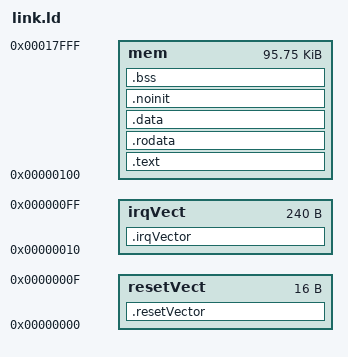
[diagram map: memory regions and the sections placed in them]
/*
 * Copyright (c) 2018 TU Dresden
 * All rights reserved.
 *
 * Redistribution and use in source and binary forms, with or without
 * modification, are permitted provided that the following conditions are
 * met: redistributions of source code must retain the above copyright
 * notice, this list of conditions and the following disclaimer;
 * redistributions in binary form must reproduce the above copyright
 * notice, this list of conditions and the following disclaimer in the
 * documentation and/or other materials provided with the distribution;
 * neither the name of the copyright holders nor the names of its
 * contributors may be used to endorse or promote products derived from
 * this software without specific prior written permission.
 *
 * THIS SOFTWARE IS PROVIDED BY THE COPYRIGHT HOLDERS AND CONTRIBUTORS
 * "AS IS" AND ANY EXPRESS OR IMPLIED WARRANTIES, INCLUDING, BUT NOT
 * LIMITED TO, THE IMPLIED WARRANTIES OF MERCHANTABILITY AND FITNESS FOR
 * A PARTICULAR PURPOSE ARE DISCLAIMED. IN NO EVENT SHALL THE COPYRIGHT
 * OWNER OR CONTRIBUTORS BE LIABLE FOR ANY DIRECT, INDIRECT, INCIDENTAL,
 * SPECIAL, EXEMPLARY, OR CONSEQUENTIAL DAMAGES (INCLUDING, BUT NOT
 * LIMITED TO, PROCUREMENT OF SUBSTITUTE GOODS OR SERVICES; LOSS OF USE,
 * DATA, OR PROFITS; OR BUSINESS INTERRUPTION) HOWEVER CAUSED AND ON ANY
 * THEORY OF LIABILITY, WHETHER IN CONTRACT, STRICT LIABILITY, OR TORT
 * (INCLUDING NEGLIGENCE OR OTHERWISE) ARISING IN ANY WAY OUT OF THE USE
 * OF THIS SOFTWARE, EVEN IF ADVISED OF THE POSSIBILITY OF SUCH DAMAGE.
 *
 * Authors: Robert Scheffel
 */

MEMORY {
    resetVect : ORIGIN = 0x00000000, LENGTH = 0x00000010
    irqVect :   ORIGIN = 0x00000010, LENGTH = 0x000000f0
    mem :       ORIGIN = 0x00000100, LENGTH = 0x00017f00
}

ENTRY(_resetVect);

SECTIONS {

    __stack = ORIGIN(mem) + LENGTH(mem) - 4;

    .resetVector : {
        _resetVect = ABSOLUTE(.);
        KEEP(*(.resetVect.text))
    } > resetVect 

    .irqVector : {
        *(.irq);
    } > irqVect


    .text :
    {
        *(.text)
        *(.text.unlikely .text.*_unlikely .text.unlikely.*)
        *(.text.exit .text.exit.*)
        *(.text.startup .text.startup.*)
        *(.text.hot .text.hot.*)
        *(.stub .text.* .gnu.linkonce.t.*)
        KEEP (*(SORT_NONE(.init)))
        KEEP (*(SORT_NONE(.fini)))
    } > mem


    .rodata : 
    {
        *(.rodata .rodata.* .gnu.linkonce.r.*)
        KEEP (*(.xt_except_table))
        KEEP (*(.gcc_except_table))
        *(.gnu.linkonce.e.*)
        *(.gnu.version_r)
        KEEP (*(.eh_frame))
        /*  C++ constructor and destructor tables, properly ordered:  */
        KEEP (*crtbegin.o(.ctors))
        KEEP (*(EXCLUDE_FILE (*crtend.o) .ctors))
        KEEP (*(SORT(.ctors.*)))
        KEEP (*(.ctors))
        KEEP (*crtbegin.o(.dtors))
        KEEP (*(EXCLUDE_FILE (*crtend.o) .dtors))
        KEEP (*(SORT(.dtors.*)))
        KEEP (*(.dtors))
        *(.gnu.linkonce.h.*)
        *(.dynamic)
        *(.gnu.version_d)
    } > mem

    .data :
    {
        *(.data .data.* .gnu.linkonce.d.*)
        *(.data1)
        PROVIDE( __global_pointer$ = . + (4K / 2) );
        *(.sdata)
        *(.sdata.*)
        *(.gnu.linkonce.s.*)
        *(.sdata2)
        *(.sdata2.*)
        *(.gnu.linkonce.s2.*)
        _edata = .;
    } > mem

    .noinit (NOLOAD): ALIGN(4)
    {
        *(.noinit .noinit.*)
    } > mem

    .bss : 
    {
        *(.dynbss)
        *(.bss .bss.* .gnu.linkonce.b.*)
        *(COMMON)
        _end = .;
    } > mem

    /* DWARF debug sections.
     Symbols in the DWARF debugging sections are relative to the beginning
     of the section so we begin them at 0.  */
    /* DWARF 1 */
    .debug          0 : { *(.debug) }
    .line           0 : { *(.line) }
    /* GNU DWARF 1 extensions */
    .debug_srcinfo  0 : { *(.debug_srcinfo) }
    .debug_sfnames  0 : { *(.debug_sfnames) }
    /* DWARF 1.1 and DWARF 2 */
    .debug_aranges  0 : { *(.debug_aranges) }
    .debug_pubnames 0 : { *(.debug_pubnames) }
    /* DWARF 2 */
    .debug_info     0 : { *(.debug_info .gnu.linkonce.wi.*) }
    .debug_abbrev   0 : { *(.debug_abbrev) }
    .debug_line     0 : { *(.debug_line .debug_line.* .debug_line_end ) }
    .debug_frame    0 : { *(.debug_frame) }
    .debug_str      0 : { *(.debug_str) }
    .debug_loc      0 : { *(.debug_loc) }
    .debug_macinfo  0 : { *(.debug_macinfo) }
    /* SGI/MIPS DWARF 2 extensions */
    .debug_weaknames 0 : { *(.debug_weaknames) }
    .debug_funcnames 0 : { *(.debug_funcnames) }
    .debug_typenames 0 : { *(.debug_typenames) }
    .debug_varnames  0 : { *(.debug_varnames) }
    /* DWARF 3 */
    .debug_pubtypes 0 : { *(.debug_pubtypes) }
    .debug_ranges   0 : { *(.debug_ranges) }
    /* DWARF Extension.  */
    .debug_macro    0 : { *(.debug_macro) }
    .debug_addr     0 : { *(.debug_addr) }
    .gnu.attributes 0 : { KEEP (*(.gnu.attributes)) }
    /DISCARD/ : { *(.note.GNU-stack) *(.gnu_debuglink) *(.gnu.lto_*) }

}
